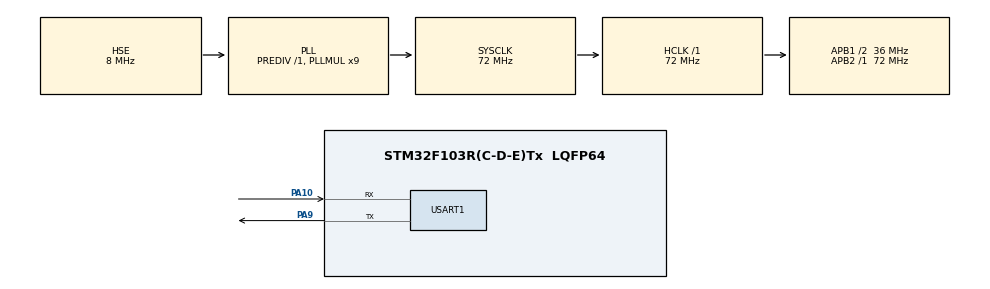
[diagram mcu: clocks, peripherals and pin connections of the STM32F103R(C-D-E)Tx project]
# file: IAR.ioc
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Mcu.Family=STM32F1
Mcu.Name=STM32F103R(C-D-E)Tx
Mcu.Package=LQFP64
NVIC.PriorityGroup=NVIC_PRIORITYGROUP_4
PA10.Mode=Asynchronous
PA10.Signal=USART1_RX
PA13.Mode=Serial_Wire
PA13.Signal=SYS_JTMS-SWDIO
PA14.Mode=Serial_Wire
PA14.Signal=SYS_JTCK-SWCLK
PA9.Mode=Asynchronous
PA9.Signal=USART1_TX
PD0-OSC_IN.Mode=HSE-External-Oscillator
PD0-OSC_IN.Signal=RCC_OSC_IN
PD1-OSC_OUT.Mode=HSE-External-Oscillator
PD1-OSC_OUT.Signal=RCC_OSC_OUT
ProjectManager.HeapSize=0x200
ProjectManager.StackSize=0x400
ProjectManager.TargetToolchain=MDK-ARM V5.32
RCC.AHBFreq_Value=72000000
RCC.APB1CLKDivider=RCC_HCLK_DIV2
RCC.APB1Freq_Value=36000000
RCC.APB1TimFreq_Value=72000000
RCC.APB2Freq_Value=72000000
RCC.APB2TimFreq_Value=72000000
RCC.HCLKFreq_Value=72000000
RCC.PLLMUL=RCC_PLL_MUL9
RCC.PLLSourceVirtual=RCC_PLLSOURCE_HSE
RCC.SYSCLKFreq_VALUE=72000000
RCC.SYSCLKSource=RCC_SYSCLKSOURCE_PLLCLK
RCC.USBFreq_Value=72000000
USART1.VirtualMode=VM_ASYNC
VP_CRC_VS_CRC.Mode=CRC_Activate
board=custom

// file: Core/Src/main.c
/* USER CODE BEGIN Header */
/**
  ******************************************************************************
  * @file           : main.c
  * @brief          : Main program body
  ******************************************************************************
  * @attention
  *
  * Copyright (c) 2026 STMicroelectronics.
  * All rights reserved.
  *
  * This software is licensed under terms that can be found in the LICENSE file
  * in the root directory of this software component.
  * If no LICENSE file comes with this software, it is provided AS-IS.
  *
  ******************************************************************************
  */
/* USER CODE END Header */
#include "main.h"
#include "crc.h"
#include "usart.h"
#include "gpio.h"

/* USER CODE BEGIN Includes */
#include "bootloader.h"
/* USER CODE END Includes */

void SystemClock_Config(void);

int main(void)
{

  /* MCU Configuration--------------------------------------------------------*/

  /* Reset of all peripherals, Initializes the Flash interface and the Systick. */
  HAL_Init();

  /* Configure the system clock */
  SystemClock_Config();

  /* Initialize all configured peripherals */
  MX_GPIO_Init();
  MX_USART1_UART_Init();
  MX_CRC_Init();
  /* USER CODE BEGIN 2 */

// 1. 如果你在 CubeMX 里开了串口，就必须在这里关掉
HAL_UART_DeInit(&huart1);

// 2. 如果你在 CubeMX 里开了 DMA，就必须在这里关掉
//HAL_DMA_DeInit(&hdma_usart1_rx);
//#0.声明�?个boot_info_t变量
boot_info_t info;

#if 1
//#1.获取BootInfo
BootInfo_Load(&info);
//测试bootinfo段有没有写入flash
if(BootInfo_Valid(&info)!=true)
{
	//第一次运行bootloder先初始化bootinfo
	BootInfo_InitDefault(&info);
	//获取BootInfo
	BootInfo_Load(&info);
}
#endif

#if 0
//先看看a/b能不能跑：修改bootinfo里面的默认分区
BootInfo_InitDefault(&info);
BootInfo_Load(&info);
#endif

//OTA状�?�机
switch(info.state)
{
	case OTA_STATE_CONFIRM:
		//APP标记有效，bootloader设置normal状�??
	info.boot_count=0;
	info.state=OTA_STATE_NORMAL;
	break;

	case OTA_STATE_PENDING:
	{
		//对新固件进行CRC校验
		app_id_t next=info.pending_app;
		uint32_t addr=Boot_GetAppAddr(next);//获取新固件地�?
		uint32_t crc=Bootloader_GetCRC(next,&info);//获取预期CRC�?
		uint32_t firmware_size=Boot_GetFirmwareSize(&info);//获取新固件大小
		if(Bootloader_CRC32_Verify(addr,crc,firmware_size)==false)
		{
			//CRC校验失败
			info.pending_app=APP_NONE;
			info.state=OTA_STATE_NORMAL;
		}
		else
		{
			//通过CRC校验，修改info参数
			info.state=OTA_STATE_TESTING;
			info.boot_count = 1;
			info.pre_app=info.active_app;
			info.active_app=info.pending_app;
			info.pending_app=APP_NONE;
		}

		break;
	}

	case OTA_STATE_TESTING:
		//新固件测试阶�?,判断有没有超出回滚次数限�?
	info.boot_count++;
	if(info.boot_count>=BOOT_ROLLBACK_COUNT){
	//超出限制，触发回�?
	Bootloader_Rollback(&info);
	}
	break;

	case OTA_STATE_NORMAL:
		break;

	default:
		break;
}

//选择运行分区，�?�过id和地�?映射获取分区地址
app_id_t id =info.active_app;
uint32_t app_addr=Boot_GetAppAddr(id);

//�?后再写入flash，写之前可以修改副本
BootInfo_Save(&info);

//HAL_Delay(5000);
//#3.跳转
bootloder_JumpToApp(app_addr);
  /* USER CODE END 2 */

  /* Infinite loop */
  while (1)
  {

  }
}

void SystemClock_Config(void)
{
  RCC_OscInitTypeDef RCC_OscInitStruct = {0};
  RCC_ClkInitTypeDef RCC_ClkInitStruct = {0};

  /** Initializes the RCC Oscillators according to the specified parameters
  * in the RCC_OscInitTypeDef structure.
  */
  RCC_OscInitStruct.OscillatorType = RCC_OSCILLATORTYPE_HSE;
  RCC_OscInitStruct.HSEState = RCC_HSE_ON;
  RCC_OscInitStruct.HSEPredivValue = RCC_HSE_PREDIV_DIV1;
  RCC_OscInitStruct.HSIState = RCC_HSI_ON;
  RCC_OscInitStruct.PLL.PLLState = RCC_PLL_ON;
  RCC_OscInitStruct.PLL.PLLSource = RCC_PLLSOURCE_HSE;
  RCC_OscInitStruct.PLL.PLLMUL = RCC_PLL_MUL9;
  if (HAL_RCC_OscConfig(&RCC_OscInitStruct) != HAL_OK)
  {
    Error_Handler();
  }

  /** Initializes the CPU, AHB and APB buses clocks
  */
  RCC_ClkInitStruct.ClockType = RCC_CLOCKTYPE_HCLK|RCC_CLOCKTYPE_SYSCLK
                              |RCC_CLOCKTYPE_PCLK1|RCC_CLOCKTYPE_PCLK2;
  RCC_ClkInitStruct.SYSCLKSource = RCC_SYSCLKSOURCE_PLLCLK;
  RCC_ClkInitStruct.AHBCLKDivider = RCC_SYSCLK_DIV1;
  RCC_ClkInitStruct.APB1CLKDivider = RCC_HCLK_DIV2;
  RCC_ClkInitStruct.APB2CLKDivider = RCC_HCLK_DIV1;

  if (HAL_RCC_ClockConfig(&RCC_ClkInitStruct, FLASH_LATENCY_2) != HAL_OK)
  {
    Error_Handler();
  }
}

void Error_Handler(void)
{
  __disable_irq();
  while (1)
  {
  }
}
